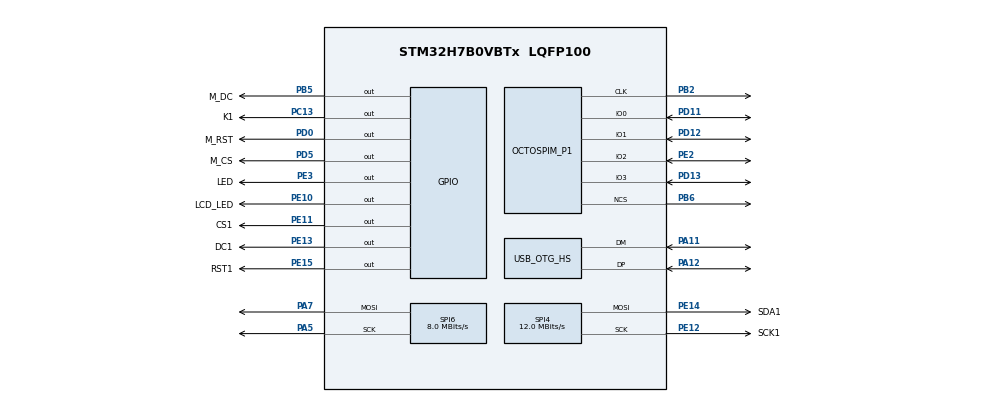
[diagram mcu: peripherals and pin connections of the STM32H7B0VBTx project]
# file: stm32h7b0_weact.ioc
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Bdma2.Request0=SPI6_TX
Bdma2.RequestsNb=1
Bdma2.SPI6_TX.0.Direction=DMA_MEMORY_TO_PERIPH
Bdma2.SPI6_TX.0.EventEnable=DISABLE
Bdma2.SPI6_TX.0.Instance=BDMA2_Channel0
Bdma2.SPI6_TX.0.MemDataAlignment=DMA_MDATAALIGN_BYTE
Bdma2.SPI6_TX.0.MemInc=DMA_MINC_ENABLE
Bdma2.SPI6_TX.0.Mode=DMA_NORMAL
Bdma2.SPI6_TX.0.PeriphDataAlignment=DMA_PDATAALIGN_BYTE
Bdma2.SPI6_TX.0.PeriphInc=DMA_PINC_DISABLE
Bdma2.SPI6_TX.0.Polarity=HAL_DMAMUX_REQ_GEN_RISING
Bdma2.SPI6_TX.0.Priority=DMA_PRIORITY_LOW
Bdma2.SPI6_TX.0.RequestNumber=1
Bdma2.SPI6_TX.0.SignalID=NONE
Bdma2.SPI6_TX.0.SyncEnable=DISABLE
Bdma2.SPI6_TX.0.SyncPolarity=HAL_DMAMUX_SYNC_NO_EVENT
Bdma2.SPI6_TX.0.SyncRequestNumber=1
Bdma2.SPI6_TX.0.SyncSignalID=NONE
Dma.Request0=SPI4_TX
Dma.SPI4_TX.0.Direction=DMA_MEMORY_TO_PERIPH
Dma.SPI4_TX.0.EventEnable=DISABLE
Dma.SPI4_TX.0.FIFOMode=DMA_FIFOMODE_DISABLE
Dma.SPI4_TX.0.Instance=DMA1_Stream0
Dma.SPI4_TX.0.MemDataAlignment=DMA_MDATAALIGN_BYTE
Dma.SPI4_TX.0.MemInc=DMA_MINC_ENABLE
Dma.SPI4_TX.0.Mode=DMA_NORMAL
Dma.SPI4_TX.0.PeriphDataAlignment=DMA_PDATAALIGN_BYTE
Dma.SPI4_TX.0.PeriphInc=DMA_PINC_DISABLE
Dma.SPI4_TX.0.Polarity=HAL_DMAMUX_REQ_GEN_RISING
Dma.SPI4_TX.0.Priority=DMA_PRIORITY_LOW
Dma.SPI4_TX.0.RequestNumber=1
Dma.SPI4_TX.0.SignalID=NONE
Dma.SPI4_TX.0.SyncEnable=DISABLE
Dma.SPI4_TX.0.SyncPolarity=HAL_DMAMUX_SYNC_NO_EVENT
Dma.SPI4_TX.0.SyncRequestNumber=1
Dma.SPI4_TX.0.SyncSignalID=NONE
Mcu.Family=STM32H7
Mcu.Name=STM32H7B0VBTx
Mcu.Package=LQFP100
NVIC.BDMA2_Channel0_IRQn=true\:0\:0\:false\:false\:true\:false\:true\:true
NVIC.DMA1_Stream0_IRQn=true\:0\:0\:false\:false\:true\:false\:true\:true
NVIC.PriorityGroup=NVIC_PRIORITYGROUP_4
NVIC.SPI4_IRQn=true\:0\:0\:false\:false\:true\:false\:true\:true
NVIC.SPI6_IRQn=true\:0\:0\:false\:false\:true\:false\:true\:true
OCTOSPI1.ChipSelectHighTime=1
OCTOSPI1.ClockPrescaler=2
OCTOSPI1.DeviceSize=23
OCTOSPI1.FifoThreshold=8
OCTOSPI1.MemoryType=HAL_OSPI_MEMTYPE_MACRONIX
OCTOSPI1.SampleShifting=HAL_OSPI_SAMPLE_SHIFTING_HALFCYCLE
PA11.Mode=Device_Only_FS
PA11.Signal=USB_OTG_HS_DM
PA12.Mode=Device_Only_FS
PA12.Signal=USB_OTG_HS_DP
PA13.Mode=Serial_Wire
PA13.Signal=DEBUG_JTMS-SWDIO
PA14.Mode=Serial_Wire
PA14.Signal=DEBUG_JTCK-SWCLK
PA5.Mode=TX_Only_Simplex_Unidirect_Master
PA5.Signal=SPI6_SCK
PA7.Mode=TX_Only_Simplex_Unidirect_Master
PA7.Signal=SPI6_MOSI
PB2.Mode=O1_P1_CLK
PB2.Signal=OCTOSPIM_P1_CLK
PB5.GPIO_Label=M_DC
PB5.GPIO_Speed=GPIO_SPEED_FREQ_VERY_HIGH
PB5.Signal=GPIO_Output
PB6.Mode=OCTOSPI1_Port1_NCS
PB6.Signal=OCTOSPIM_P1_NCS
PC13.GPIO_Label=K1
PC13.Signal=GPIO_Output
PC14-OSC32_IN.Mode=LSE-External-Oscillator
PC14-OSC32_IN.Signal=RCC_OSC32_IN
PC15-OSC32_OUT.Mode=LSE-External-Oscillator
PC15-OSC32_OUT.Signal=RCC_OSC32_OUT
PD0.GPIO_Label=M_RST
PD0.GPIO_Speed=GPIO_SPEED_FREQ_VERY_HIGH
PD0.Signal=GPIO_Output
PD11.Mode=OCTOSPI1_IOL_Port1L
PD11.Signal=OCTOSPIM_P1_IO0
PD12.Mode=OCTOSPI1_IOL_Port1L
PD12.Signal=OCTOSPIM_P1_IO1
PD13.Mode=OCTOSPI1_IOL_Port1L
PD13.Signal=OCTOSPIM_P1_IO3
PD5.GPIO_Label=M_CS
PD5.GPIO_Speed=GPIO_SPEED_FREQ_VERY_HIGH
PD5.Signal=GPIO_Output
PE10.GPIO_Label=LCD_LED
PE10.GPIO_Speed=GPIO_SPEED_FREQ_LOW
PE10.PinState=GPIO_PIN_RESET
PE10.Signal=GPIO_Output
PE11.GPIO_Label=CS1
PE11.GPIO_Speed=GPIO_SPEED_FREQ_LOW
PE11.PinState=GPIO_PIN_RESET
PE11.Signal=GPIO_Output
PE12.GPIO_Label=SCK1
PE12.Mode=TX_Only_Simplex_Unidirect_Master
PE12.Signal=SPI4_SCK
PE13.GPIO_Label=DC1
PE13.GPIO_Speed=GPIO_SPEED_FREQ_LOW
PE13.PinState=GPIO_PIN_RESET
PE13.Signal=GPIO_Output
PE14.GPIO_Label=SDA1
PE14.Mode=TX_Only_Simplex_Unidirect_Master
PE14.Signal=SPI4_MOSI
PE15.GPIO_Label=RST1
PE15.GPIO_Speed=GPIO_SPEED_FREQ_LOW
PE15.PinState=GPIO_PIN_RESET
PE15.Signal=GPIO_Output
PE2.Mode=OCTOSPI1_IOL_Port1L
PE2.Signal=OCTOSPIM_P1_IO2
PE3.GPIO_Label=LED
PE3.GPIO_Speed=GPIO_SPEED_FREQ_LOW
PE3.PinState=GPIO_PIN_RESET
PE3.Signal=GPIO_Output
PH0-OSC_IN.Mode=HSE-External-Oscillator
PH0-OSC_IN.Signal=RCC_OSC_IN
PH1-OSC_OUT.Mode=HSE-External-Oscillator
PH1-OSC_OUT.Signal=RCC_OSC_OUT
ProjectManager.HeapSize=0x200
ProjectManager.StackSize=0x400
ProjectManager.TargetToolchain=Makefile
RCC.ADCCLockSelection=RCC_ADCCLKSOURCE_PLL3
RCC.ADCFreq_Value=48000000
RCC.APB1Freq_Value=32000000
RCC.APB2Freq_Value=32000000
RCC.APB3Freq_Value=32000000
RCC.APB4Freq_Value=32000000
RCC.CDPPRE=RCC_APB3_DIV2
RCC.CDPPRE1=RCC_APB1_DIV2
RCC.CDPPRE2=RCC_APB2_DIV2
RCC.CortexFreq_Value=64000000
RCC.DIVM1=5
RCC.DIVM2=25
RCC.DIVM3=25
RCC.DIVN1=112
RCC.DIVN2=172
RCC.DIVN3=144
RCC.DIVQ1=4
RCC.DIVQ2=4
RCC.DIVQ3=3
RCC.DIVR3=3
RCC.HCLKFreq_Value=64000000
RCC.HSE_VALUE=25000000
RCC.PLLSourceVirtual=RCC_PLLSOURCE_HSE
RCC.SPI6CLockSelection=RCC_SPI6CLKSOURCE_HSI
RCC.SRDPPRE=RCC_APB4_DIV2
RCC.SYSCLKFreq_VALUE=64000000
RCC.Spi45ClockSelection=RCC_SPI45CLKSOURCE_PLL3
RCC.USART16CLockSelection=RCC_USART16910CLKSOURCE_PLL2
RCC.USBCLockSelection=RCC_USBCLKSOURCE_HSI48
RCC.USBFreq_Value=48000000
SPI4.BaudRatePrescaler=SPI_BAUDRATEPRESCALER_4
SPI4.CalculateBaudRate=12.0 MBits/s
SPI4.DataSize=SPI_DATASIZE_8BIT
SPI4.Direction=SPI_DIRECTION_2LINES_TXONLY
SPI4.Mode=SPI_MODE_MASTER
SPI4.VirtualType=VM_MASTER
SPI6.BaudRatePrescaler=SPI_BAUDRATEPRESCALER_8
SPI6.CLKPhase=SPI_PHASE_1EDGE
SPI6.CLKPolarity=SPI_POLARITY_HIGH
SPI6.CalculateBaudRate=8.0 MBits/s
SPI6.DataSize=SPI_DATASIZE_8BIT
SPI6.Direction=SPI_DIRECTION_2LINES_TXONLY
SPI6.Mode=SPI_MODE_MASTER
SPI6.VirtualType=VM_MASTER
TIM17.Prescaler=279
USB_OTG_HS.VirtualMode-Device_Only_FS=Device_Only_FS
VP_OCTOSPI1_VS_quad.Mode=quad_mode
VP_RTC_VS_RTC_Activate.Mode=RTC_Enabled
VP_RTC_VS_RTC_Calendar.Mode=RTC_Calendar
VP_TIM17_VS_ClockSourceINT.Mode=Enable_Timer
board=custom

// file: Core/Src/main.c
/* USER CODE BEGIN Header */
/**
  ******************************************************************************
  * @file           : main.c
  * @brief          : Main program body
  ******************************************************************************
  * @attention
  *
  * Copyright (c) 2024 STMicroelectronics.
  * All rights reserved.
  *
  * This software is licensed under terms that can be found in the LICENSE file
  * in the root directory of this software component.
  * If no LICENSE file comes with this software, it is provided AS-IS.
  *
  ******************************************************************************
  */
/* USER CODE END Header */
#include "main.h"

/* USER CODE BEGIN Includes */
#include "core.h"
/* USER CODE END Includes */

OSPI_HandleTypeDef hospi1;

RTC_HandleTypeDef hrtc;

SPI_HandleTypeDef hspi4;
SPI_HandleTypeDef hspi6;
DMA_HandleTypeDef hdma_spi4_tx;
DMA_HandleTypeDef hdma_spi6_tx;

TIM_HandleTypeDef htim17;

PCD_HandleTypeDef hpcd_USB_OTG_HS;

void SystemClock_Config(void);
static void MX_GPIO_Init(void);
static void MX_BDMA2_Init(void);
static void MX_DMA_Init(void);
static void MX_SPI4_Init(void);
static void MX_TIM17_Init(void);
static void MX_SPI6_Init(void);
static void MX_USB_OTG_HS_PCD_Init(void);
static void MX_OCTOSPI1_Init(void);
static void MX_RTC_Init(void);

int main(void)
{

  /* MCU Configuration--------------------------------------------------------*/

  /* Reset of all peripherals, Initializes the Flash interface and the Systick. */
  HAL_Init();

  /* Configure the system clock */
  SystemClock_Config();

  /* Initialize all configured peripherals */
  MX_GPIO_Init();
  MX_BDMA2_Init();
  MX_DMA_Init();
  MX_SPI4_Init();
  MX_TIM17_Init();
  MX_SPI6_Init();
  MX_USB_OTG_HS_PCD_Init();
  MX_OCTOSPI1_Init();
  MX_RTC_Init();

  /* Infinite loop */
  /* USER CODE BEGIN WHILE */
  core();
  while (1)
  {
    /* USER CODE END WHILE */

  }
}

void SystemClock_Config(void)
{
  RCC_OscInitTypeDef RCC_OscInitStruct = {0};
  RCC_ClkInitTypeDef RCC_ClkInitStruct = {0};

  /*AXI clock gating */
  RCC->CKGAENR = 0xFFFFFFFF;

  /** Supply configuration update enable
  */
  HAL_PWREx_ConfigSupply(PWR_LDO_SUPPLY);

  /** Configure the main internal regulator output voltage
  */
  __HAL_PWR_VOLTAGESCALING_CONFIG(PWR_REGULATOR_VOLTAGE_SCALE3);

  while(!__HAL_PWR_GET_FLAG(PWR_FLAG_VOSRDY)) {}

  /** Macro to configure the PLL clock source
  */
  __HAL_RCC_PLL_PLLSOURCE_CONFIG(RCC_PLLSOURCE_HSE);

  /** Initializes the RCC Oscillators according to the specified parameters
  * in the RCC_OscInitTypeDef structure.
  */
  RCC_OscInitStruct.OscillatorType = RCC_OSCILLATORTYPE_HSI48|RCC_OSCILLATORTYPE_HSI
                              |RCC_OSCILLATORTYPE_LSI|RCC_OSCILLATORTYPE_HSE;
  RCC_OscInitStruct.HSEState = RCC_HSE_ON;
  RCC_OscInitStruct.HSIState = RCC_HSI_DIV1;
  RCC_OscInitStruct.HSICalibrationValue = 64;
  RCC_OscInitStruct.LSIState = RCC_LSI_ON;
  RCC_OscInitStruct.HSI48State = RCC_HSI48_ON;
  RCC_OscInitStruct.PLL.PLLState = RCC_PLL_NONE;
  if (HAL_RCC_OscConfig(&RCC_OscInitStruct) != HAL_OK)
  {
    Error_Handler();
  }

  /** Initializes the CPU, AHB and APB buses clocks
  */
  RCC_ClkInitStruct.ClockType = RCC_CLOCKTYPE_HCLK|RCC_CLOCKTYPE_SYSCLK
                              |RCC_CLOCKTYPE_PCLK1|RCC_CLOCKTYPE_PCLK2
                              |RCC_CLOCKTYPE_D3PCLK1|RCC_CLOCKTYPE_D1PCLK1;
  RCC_ClkInitStruct.SYSCLKSource = RCC_SYSCLKSOURCE_HSI;
  RCC_ClkInitStruct.SYSCLKDivider = RCC_SYSCLK_DIV1;
  RCC_ClkInitStruct.AHBCLKDivider = RCC_HCLK_DIV1;
  RCC_ClkInitStruct.APB3CLKDivider = RCC_APB3_DIV2;
  RCC_ClkInitStruct.APB1CLKDivider = RCC_APB1_DIV2;
  RCC_ClkInitStruct.APB2CLKDivider = RCC_APB2_DIV2;
  RCC_ClkInitStruct.APB4CLKDivider = RCC_APB4_DIV2;

  if (HAL_RCC_ClockConfig(&RCC_ClkInitStruct, FLASH_LATENCY_2) != HAL_OK)
  {
    Error_Handler();
  }
}

static void MX_OCTOSPI1_Init(void)
{

  OSPIM_CfgTypeDef sOspiManagerCfg = {0};

  /* OCTOSPI1 parameter configuration*/
  hospi1.Instance = OCTOSPI1;
  hospi1.Init.FifoThreshold = 8;
  hospi1.Init.DualQuad = HAL_OSPI_DUALQUAD_DISABLE;
  hospi1.Init.MemoryType = HAL_OSPI_MEMTYPE_MACRONIX;
  hospi1.Init.DeviceSize = 23;
  hospi1.Init.ChipSelectHighTime = 1;
  hospi1.Init.FreeRunningClock = HAL_OSPI_FREERUNCLK_DISABLE;
  hospi1.Init.ClockMode = HAL_OSPI_CLOCK_MODE_0;
  hospi1.Init.WrapSize = HAL_OSPI_WRAP_NOT_SUPPORTED;
  hospi1.Init.ClockPrescaler = 2;
  hospi1.Init.SampleShifting = HAL_OSPI_SAMPLE_SHIFTING_HALFCYCLE;
  hospi1.Init.DelayHoldQuarterCycle = HAL_OSPI_DHQC_DISABLE;
  hospi1.Init.ChipSelectBoundary = 0;
  hospi1.Init.DelayBlockBypass = HAL_OSPI_DELAY_BLOCK_BYPASSED;
  hospi1.Init.MaxTran = 0;
  hospi1.Init.Refresh = 0;
  if (HAL_OSPI_Init(&hospi1) != HAL_OK)
  {
    Error_Handler();
  }
  sOspiManagerCfg.ClkPort = 1;
  sOspiManagerCfg.NCSPort = 1;
  sOspiManagerCfg.IOLowPort = HAL_OSPIM_IOPORT_1_LOW;
  if (HAL_OSPIM_Config(&hospi1, &sOspiManagerCfg, HAL_OSPI_TIMEOUT_DEFAULT_VALUE) != HAL_OK)
  {
    Error_Handler();
  }

}

static void MX_RTC_Init(void)
{

  RTC_TimeTypeDef sTime = {0};
  RTC_DateTypeDef sDate = {0};

  /** Initialize RTC Only
  */
  hrtc.Instance = RTC;
  hrtc.Init.HourFormat = RTC_HOURFORMAT_24;
  hrtc.Init.AsynchPrediv = 127;
  hrtc.Init.SynchPrediv = 255;
  hrtc.Init.OutPut = RTC_OUTPUT_DISABLE;
  hrtc.Init.OutPutPolarity = RTC_OUTPUT_POLARITY_HIGH;
  hrtc.Init.OutPutType = RTC_OUTPUT_TYPE_OPENDRAIN;
  hrtc.Init.OutPutRemap = RTC_OUTPUT_REMAP_NONE;
  if (HAL_RTC_Init(&hrtc) != HAL_OK)
  {
    Error_Handler();
  }

  /** Initialize RTC and set the Time and Date
  */
  sTime.Hours = 0x0;
  sTime.Minutes = 0x0;
  sTime.Seconds = 0x0;
  sTime.DayLightSaving = RTC_DAYLIGHTSAVING_NONE;
  sTime.StoreOperation = RTC_STOREOPERATION_RESET;
  if (HAL_RTC_SetTime(&hrtc, &sTime, RTC_FORMAT_BCD) != HAL_OK)
  {
    Error_Handler();
  }
  sDate.WeekDay = RTC_WEEKDAY_MONDAY;
  sDate.Month = RTC_MONTH_JANUARY;
  sDate.Date = 0x1;
  sDate.Year = 0x0;

  if (HAL_RTC_SetDate(&hrtc, &sDate, RTC_FORMAT_BCD) != HAL_OK)
  {
    Error_Handler();
  }

}

static void MX_SPI4_Init(void)
{

  /* SPI4 parameter configuration*/
  hspi4.Instance = SPI4;
  hspi4.Init.Mode = SPI_MODE_MASTER;
  hspi4.Init.Direction = SPI_DIRECTION_2LINES_TXONLY;
  hspi4.Init.DataSize = SPI_DATASIZE_8BIT;
  hspi4.Init.CLKPolarity = SPI_POLARITY_LOW;
  hspi4.Init.CLKPhase = SPI_PHASE_1EDGE;
  hspi4.Init.NSS = SPI_NSS_SOFT;
  hspi4.Init.BaudRatePrescaler = SPI_BAUDRATEPRESCALER_4;
  hspi4.Init.FirstBit = SPI_FIRSTBIT_MSB;
  hspi4.Init.TIMode = SPI_TIMODE_DISABLE;
  hspi4.Init.CRCCalculation = SPI_CRCCALCULATION_DISABLE;
  hspi4.Init.CRCPolynomial = 0x0;
  hspi4.Init.NSSPMode = SPI_NSS_PULSE_ENABLE;
  hspi4.Init.NSSPolarity = SPI_NSS_POLARITY_LOW;
  hspi4.Init.FifoThreshold = SPI_FIFO_THRESHOLD_01DATA;
  hspi4.Init.TxCRCInitializationPattern = SPI_CRC_INITIALIZATION_ALL_ZERO_PATTERN;
  hspi4.Init.RxCRCInitializationPattern = SPI_CRC_INITIALIZATION_ALL_ZERO_PATTERN;
  hspi4.Init.MasterSSIdleness = SPI_MASTER_SS_IDLENESS_00CYCLE;
  hspi4.Init.MasterInterDataIdleness = SPI_MASTER_INTERDATA_IDLENESS_00CYCLE;
  hspi4.Init.MasterReceiverAutoSusp = SPI_MASTER_RX_AUTOSUSP_DISABLE;
  hspi4.Init.MasterKeepIOState = SPI_MASTER_KEEP_IO_STATE_DISABLE;
  hspi4.Init.IOSwap = SPI_IO_SWAP_DISABLE;
  if (HAL_SPI_Init(&hspi4) != HAL_OK)
  {
    Error_Handler();
  }

}

static void MX_SPI6_Init(void)
{

  /* SPI6 parameter configuration*/
  hspi6.Instance = SPI6;
  hspi6.Init.Mode = SPI_MODE_MASTER;
  hspi6.Init.Direction = SPI_DIRECTION_2LINES_TXONLY;
  hspi6.Init.DataSize = SPI_DATASIZE_8BIT;
  hspi6.Init.CLKPolarity = SPI_POLARITY_HIGH;
  hspi6.Init.CLKPhase = SPI_PHASE_2EDGE;
  hspi6.Init.NSS = SPI_NSS_SOFT;
  hspi6.Init.BaudRatePrescaler = SPI_BAUDRATEPRESCALER_8;
  hspi6.Init.FirstBit = SPI_FIRSTBIT_MSB;
  hspi6.Init.TIMode = SPI_TIMODE_DISABLE;
  hspi6.Init.CRCCalculation = SPI_CRCCALCULATION_DISABLE;
  hspi6.Init.CRCPolynomial = 0x0;
  hspi6.Init.NSSPMode = SPI_NSS_PULSE_ENABLE;
  hspi6.Init.NSSPolarity = SPI_NSS_POLARITY_LOW;
  hspi6.Init.FifoThreshold = SPI_FIFO_THRESHOLD_01DATA;
  hspi6.Init.TxCRCInitializationPattern = SPI_CRC_INITIALIZATION_ALL_ZERO_PATTERN;
  hspi6.Init.RxCRCInitializationPattern = SPI_CRC_INITIALIZATION_ALL_ZERO_PATTERN;
  hspi6.Init.MasterSSIdleness = SPI_MASTER_SS_IDLENESS_00CYCLE;
  hspi6.Init.MasterInterDataIdleness = SPI_MASTER_INTERDATA_IDLENESS_00CYCLE;
  hspi6.Init.MasterReceiverAutoSusp = SPI_MASTER_RX_AUTOSUSP_DISABLE;
  hspi6.Init.MasterKeepIOState = SPI_MASTER_KEEP_IO_STATE_DISABLE;
  hspi6.Init.IOSwap = SPI_IO_SWAP_DISABLE;
  if (HAL_SPI_Init(&hspi6) != HAL_OK)
  {
    Error_Handler();
  }

}

static void MX_TIM17_Init(void)
{

  htim17.Instance = TIM17;
  htim17.Init.Prescaler = 279;
  htim17.Init.CounterMode = TIM_COUNTERMODE_UP;
  htim17.Init.Period = 65535;
  htim17.Init.ClockDivision = TIM_CLOCKDIVISION_DIV1;
  htim17.Init.RepetitionCounter = 0;
  htim17.Init.AutoReloadPreload = TIM_AUTORELOAD_PRELOAD_DISABLE;
  if (HAL_TIM_Base_Init(&htim17) != HAL_OK)
  {
    Error_Handler();
  }

}

static void MX_USB_OTG_HS_PCD_Init(void)
{

  hpcd_USB_OTG_HS.Instance = USB_OTG_HS;
  hpcd_USB_OTG_HS.Init.dev_endpoints = 9;
  hpcd_USB_OTG_HS.Init.speed = PCD_SPEED_FULL;
  hpcd_USB_OTG_HS.Init.dma_enable = DISABLE;
  hpcd_USB_OTG_HS.Init.phy_itface = USB_OTG_EMBEDDED_PHY;
  hpcd_USB_OTG_HS.Init.Sof_enable = DISABLE;
  hpcd_USB_OTG_HS.Init.low_power_enable = DISABLE;
  hpcd_USB_OTG_HS.Init.lpm_enable = DISABLE;
  hpcd_USB_OTG_HS.Init.vbus_sensing_enable = DISABLE;
  hpcd_USB_OTG_HS.Init.use_dedicated_ep1 = DISABLE;
  hpcd_USB_OTG_HS.Init.use_external_vbus = DISABLE;
  if (HAL_PCD_Init(&hpcd_USB_OTG_HS) != HAL_OK)
  {
    Error_Handler();
  }

}

static void MX_BDMA2_Init(void)
{

  /* DMA controller clock enable */
  __HAL_RCC_BDMA2_CLK_ENABLE();

  /* DMA interrupt init */
  /* BDMA2_Channel0_IRQn interrupt configuration */
  HAL_NVIC_SetPriority(BDMA2_Channel0_IRQn, 0, 0);
  HAL_NVIC_EnableIRQ(BDMA2_Channel0_IRQn);

}

static void MX_DMA_Init(void)
{

  /* DMA controller clock enable */
  __HAL_RCC_DMA1_CLK_ENABLE();

  /* DMA interrupt init */
  /* DMA1_Stream0_IRQn interrupt configuration */
  HAL_NVIC_SetPriority(DMA1_Stream0_IRQn, 0, 0);
  HAL_NVIC_EnableIRQ(DMA1_Stream0_IRQn);

}

static void MX_GPIO_Init(void)
{
  GPIO_InitTypeDef GPIO_InitStruct = {0};

  /* GPIO Ports Clock Enable */
  __HAL_RCC_GPIOE_CLK_ENABLE();
  __HAL_RCC_GPIOC_CLK_ENABLE();
  __HAL_RCC_GPIOH_CLK_ENABLE();
  __HAL_RCC_GPIOA_CLK_ENABLE();
  __HAL_RCC_GPIOB_CLK_ENABLE();
  __HAL_RCC_GPIOD_CLK_ENABLE();

  /*Configure GPIO pin Output Level */
  HAL_GPIO_WritePin(GPIOE, LED_Pin|LCD_LED_Pin|CS1_Pin|DC1_Pin
                          |RST1_Pin, GPIO_PIN_RESET);

  /*Configure GPIO pin Output Level */
  HAL_GPIO_WritePin(K1_GPIO_Port, K1_Pin, GPIO_PIN_RESET);

  /*Configure GPIO pin Output Level */
  HAL_GPIO_WritePin(GPIOD, M_RST_Pin|M_CS_Pin, GPIO_PIN_RESET);

  /*Configure GPIO pin Output Level */
  HAL_GPIO_WritePin(M_DC_GPIO_Port, M_DC_Pin, GPIO_PIN_RESET);

  /*Configure GPIO pins : LED_Pin LCD_LED_Pin CS1_Pin DC1_Pin
                           RST1_Pin */
  GPIO_InitStruct.Pin = LED_Pin|LCD_LED_Pin|CS1_Pin|DC1_Pin
                          |RST1_Pin;
  GPIO_InitStruct.Mode = GPIO_MODE_OUTPUT_PP;
  GPIO_InitStruct.Pull = GPIO_NOPULL;
  GPIO_InitStruct.Speed = GPIO_SPEED_FREQ_LOW;
  HAL_GPIO_Init(GPIOE, &GPIO_InitStruct);

  /*Configure GPIO pin : K1_Pin */
  GPIO_InitStruct.Pin = K1_Pin;
  GPIO_InitStruct.Mode = GPIO_MODE_OUTPUT_PP;
  GPIO_InitStruct.Pull = GPIO_NOPULL;
  GPIO_InitStruct.Speed = GPIO_SPEED_FREQ_LOW;
  HAL_GPIO_Init(K1_GPIO_Port, &GPIO_InitStruct);

  /*Configure GPIO pins : M_RST_Pin M_CS_Pin */
  GPIO_InitStruct.Pin = M_RST_Pin|M_CS_Pin;
  GPIO_InitStruct.Mode = GPIO_MODE_OUTPUT_PP;
  GPIO_InitStruct.Pull = GPIO_NOPULL;
  GPIO_InitStruct.Speed = GPIO_SPEED_FREQ_VERY_HIGH;
  HAL_GPIO_Init(GPIOD, &GPIO_InitStruct);

  /*Configure GPIO pin : M_DC_Pin */
  GPIO_InitStruct.Pin = M_DC_Pin;
  GPIO_InitStruct.Mode = GPIO_MODE_OUTPUT_PP;
  GPIO_InitStruct.Pull = GPIO_NOPULL;
  GPIO_InitStruct.Speed = GPIO_SPEED_FREQ_VERY_HIGH;
  HAL_GPIO_Init(M_DC_GPIO_Port, &GPIO_InitStruct);

}

void Error_Handler(void)
{
  __disable_irq();
  while (1)
  {
  }
}
